# EDMA3TC register map
Vendor: Texas Instruments
Peripheral module from a debugger description file (folder am335x).
Registers are 32-bit, read-only, no defined reset value unless marked. A register's access mark holds for its fields unless they carry their own. Offsets are as the file gives them; lines under a group give offsets from that group; [hi:lo] are bit positions; {n}, {i} and the like mark numbered series; 'fields as' and 'values as' point back to an identical list; <NAME> marks a mode.

## EDMA3TC
0x00 PID — The peripheral identification register (PID) is a constant register that uniquely identifies the EDMA3TC and specific revision of the EDMA3TC.
  [31:0] PID — Peripheral identifier, value 0 to FFFF FFFFh. Reset for PID[31] to PID[16] is 0333h. Reset for PID[15] to PID[0] is 4425h.
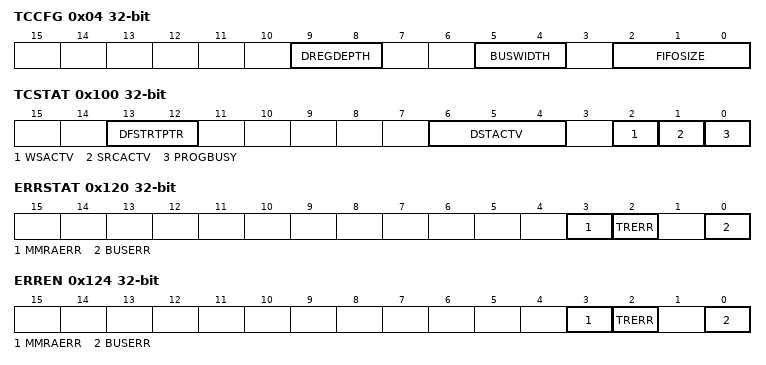
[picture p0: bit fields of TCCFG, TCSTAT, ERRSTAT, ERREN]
0x04 TCCFG
  [9:8] DREGDEPTH — Destination register FIFO depth parameterization.
  [5:4] BUSWIDTH — Bus width parameterization.
  [2:0] FIFOSIZE
0x100 TCSTAT
  [13:12] DFSTRTPTR — Destination FIFO start pointer. Represents the offset to the head entry of the destination register FIFO, in units of entries. Value 0 to 3h.
  [6:4] DSTACTV — Destination active state. Specifies the number of transfer requests (TRs) that are resident in the destination register FIFO at a given instant. This bit field can be primarily used for advanced debugging. Legal values are constrained by the destination register FIFO depth parameterization (DSTREGDEPTH) parameter.
  [2] WSACTV — Write status active
  [1] SRCACTV — Source active state
  [0] PROGBUSY — Program register set busy
0x120 ERRSTAT
  [3] MMRAERR — MMR address error.
  [2] TRERR — Transfer request (TR) error event.
  [0] BUSERR — Bus error event.
0x124 ERREN access per field — When any of the enable bits are set, a bit set in the corresponding ERRSTAT causes an assertion of the EDMA3TC interrupt.
  [3] MMRAERR rw — Interrupt enable for MMR address error (MMRAERR).
  [2] TRERR rw — Interrupt enable for transfer request error (TRERR).
  [0] BUSERR rw — Interrupt enable for bus error (BUSERR).
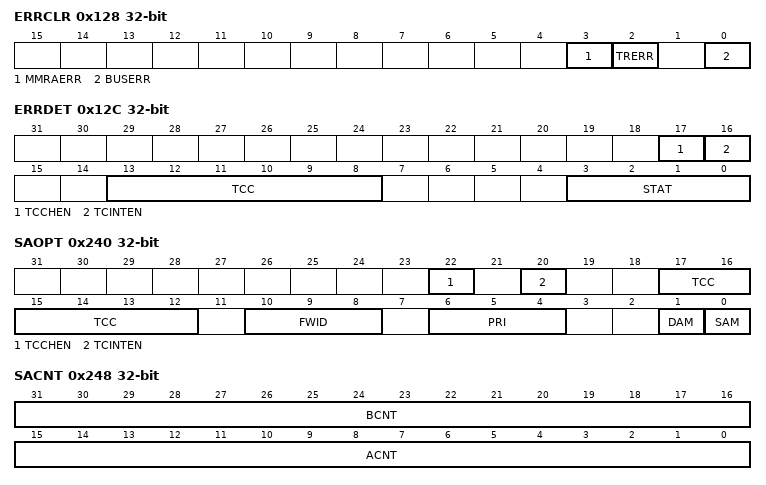
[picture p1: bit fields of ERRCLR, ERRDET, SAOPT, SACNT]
0x128 ERRCLR access per field
  [3] MMRAERR wo — Interrupt enable clear for the MMRAERR bit in the error status register (ERRSTAT).
  [2] TRERR wo — Interrupt enable clear for the TRERR bit in the error status register (ERRSTAT).
  [0] BUSERR wo — Interrupt clear for the BUSERR bit in the error status register (ERRSTAT).
0x12C ERRDET
  [17] TCCHEN — Transfer completion chaining enable. Contains the TCCHEN value in the channel options parameter (OPT) programmed by the channel controller for the read or write transaction that resulted in an error.
  [16] TCINTEN — Transfer completion interrupt enable. Contains the TCINTEN value in the channel options parameter (OPT) programmed by the channel controller for the read or write transaction that resulted in an error.
  [13:8] TCC — Transfer complete code. Contains the TCC value in the channel options parameter (OPT) programmed by the channel controller for the read or write transaction that resulted in an error.
  [3:0] STAT — Transaction status. Stores the nonzero status/error code that was detected on the read status or write status bus. If read status and write status are returned on the same cycle, then the EDMA3TC chooses nonzero version. If both are nonzero, then the write status is treated as higher priority.
0x130 ERRCMD access per field
  [0] EVAL wo — Error evaluate
0x140 RDRATE access per field — The EDMA3 transfer controller issues read commands at a rate controlled by the read rate register (RDRATE). The RDRATE defines the number of idle cycles that the read controller must wait before issuing subsequent commands. This applies both to commands within a transfer request packet (TRP) and for commands that are issued for different transfer requests (TRs). For instance, if RDRATE is set to 4 cycles between reads, there are 3 inactive cycles between reads. RDRATE allows flexibility in transfer controller access requests to an endpoint. For an application, RDRATE can be manipulated to slow down the access rate, so that the endpoint may service requests from other masters during the inactive EDMA3TC cycles. Note: The RDRATE value for a transfer controller is expected to be static, as it is decided based on the application requirement. It is not recommended to change the RDRATE value on the fly.
  [2:0] RDRATE rw — Read rate. Controls the number of cycles between read commands. This is a global setting that applies to all TRs for this EDMA3TC.
0x240 SAOPT access per field — The Source Active Options Register (SAOPT) is an EDMA3TC channel register. The EDMA3TC channel registers are split into three parts: the programming registers, the source active registers, and the destination FIFO register. The program register set is programmed by the channel controller, and is for internal use. The other two sets are read-only and provided to facilitate advanced debug capabilities. The number of destination FIFO register sets depends on the destination FIFO depth. TC0 has a FIFO depth of 2, so there are two sets of destination FIFO registers associated with TC0. TC1, TC2, and TC3 have a destination FIFO depth of 4, so there are four sets of destination FIFO registers for each of these transfer controllers.
  [22] TCCHEN rw — Transfer complete chaining enable
  [20] TCINTEN rw — Transfer complete interrupt enable.
  [17:12] TCC rw — Transfer complete code. This 6 bit code is used to set the relevant bit in CER or IPR of the EDMA3PCC module.
  [10:8] FWID rw — FIFO width. Applies if either SAM or DAM is set to constant addressing mode.
  [6:4] PRI rw — Transfer priority. Reflects the values programmed in the QUEPRI register in the EDMACC.
  [1] DAM rw — Destination address mode within an array
  [0] SAM rw — Source address mode within an array
0x244 SASRC — The Source Active Source Address Register (SASRC) is an EDMA3TC channel register. The EDMA3TC channel registers are split into three parts: the programming registers, the source active registers, and the destination FIFO register. The program register set is programmed by the channel controller, and is for internal use. The other two sets are read-only and provided to facilitate advanced debug capabilities. The number of destination FIFO register sets depends on the destination FIFO depth. TC0 has a FIFO depth of 2, so there are two sets of destination FIFO registers associated with TC0. TC1, TC2, and TC3 have a destination FIFO depth of 4, so there are four sets of destination FIFO registers for each of these transfer controllers.
  [31:0] SADDR — Source address for program register set. EDMA3TC updates value according to source addressing mode (SAM bit in the source active options register, SAOPT). Value 0 to FFFFh.
0x248 SACNT — The Source Active Count Register (SACNT) is an EDMA3TC channel register. The EDMA3TC channel registers are split into three parts: the programming registers, the source active registers, and the destination FIFO register. The program register set is programmed by the channel controller, and is for internal use. The other two sets are read-only and provided to facilitate advanced debug capabilities. The number of destination FIFO register sets depends on the destination FIFO depth. TC0 has a FIFO depth of 2, so there are two sets of destination FIFO registers associated with TC0. TC1, TC2, and TC3 have a destination FIFO depth of 4, so there are four sets of destination FIFO registers for each of these transfer controllers.
  [31:16] BCNT — B dimension count. Number of arrays to be transferred, where each array is ACNT in length. It is decremented after each read command appropriately. Represents the amount of data remaining to be read. It should be 0 when transfer request (TR) is complete. Value 0 to FFFFh.
  [15:0] ACNT — A dimension count. Number of bytes to be transferred in first dimension. It is decremented after each read command appropriately. Represents the amount of data remaining to be read. It should be 0 when transfer request (TR) is complete. Value 0 to FFFFh.
0x24C SADST — The Source Active Destination Address Register (SADST) is an EDMA3TC channel register. The EDMA3TC channel registers are split into three parts: the programming registers, the source active registers, and the destination FIFO register. The program register set is programmed by the channel controller, and is for internal use. The other two sets are read-only and provided to facilitate advanced debug capabilities. The number of destination FIFO register sets depends on the destination FIFO depth. TC0 has a FIFO depth of 2, so there are two sets of destination FIFO registers associated with TC0. TC1, TC2, and TC3 have a destination FIFO depth of 4, so there are four sets of destination FIFO registers for each of these transfer controllers.
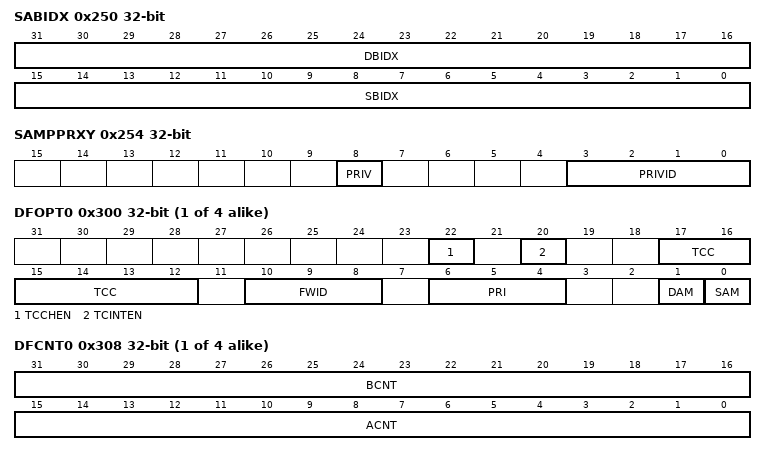
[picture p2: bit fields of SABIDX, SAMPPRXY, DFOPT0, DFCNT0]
0x250 SABIDX — The Source Active Source B-Dimension Index Register (SABIDX) is an EDMA3TC channel register. The EDMA3TC channel registers are split into three parts: the programming registers, the source active registers, and the destination FIFO register. The program register set is programmed by the channel controller, and is for internal use. The other two sets are read-only and provided to facilitate advanced debug capabilities. The number of destination FIFO register sets depends on the destination FIFO depth. TC0 has a FIFO depth of 2, so there are two sets of destination FIFO registers associated with TC0. TC1, TC2, and TC3 have a destination FIFO depth of 4, so there are four sets of destination FIFO registers for each of these transfer controllers.
  [31:16] DBIDX — B-Index offset between destination arrays. Represents the offset in bytes between the starting address of each destination. Always reads as 0.
  [15:0] SBIDX — B-Index offset between source arrays. Represents the offset in bytes between the starting address of each source array. Value 0 to FFFFh.
0x254 SAMPPRXY — The Source Active Memory Protection Proxy Register (SAMPPRXY) is an EDMA3TC channel register. The EDMA3TC channel registers are split into three parts: the programming registers, the source active registers, and the destination FIFO register. The program register set is programmed by the channel controller, and is for internal use. The other two sets are read-only and provided to facilitate advanced debug capabilities. The number of destination FIFO register sets depends on the destination FIFO depth. TC0 has a FIFO depth of 2, so there are two sets of destination FIFO registers associated with TC0. TC1, TC2, and TC3 have a destination FIFO depth of 4, so there are four sets of destination FIFO registers for each of these transfer controllers.
  [8] PRIV — Privilege level. The privilege level used by the host to set up the parameter entry in the channel controller. This field is set up when the associated TR is submitted to the EDMA3TC. The privilege ID is used while issuing read and write command to the target endpoints so that the target endpoints can perform memory protection checks based on the PRIV of the host that set up the DMA transaction.
  [3:0] PRIVID — Privilege ID. This contains the privilege ID of the host that set up the parameter entry in the channel controller. This field is set up when the associated TR is submitted to the EDMA3TC. This PRIVID value is used while issuing read and write commands to the target endpoints so that the target endpoints can perform memory protection checks based on the PRIVID of the host that set up the DMA transaction. Value 0 to Fh.
0x258 SACNTRLD — The Source Active Count Reload Register (SACNTRLD) is an EDMA3TC channel register. The EDMA3TC channel registers are split into three parts: the programming registers, the source active registers, and the destination FIFO register. The program register set is programmed by the channel controller, and is for internal use. The other two sets are read-only and provided to facilitate advanced debug capabilities. The number of destination FIFO register sets depends on the destination FIFO depth. TC0 has a FIFO depth of 2, so there are two sets of destination FIFO registers associated with TC0. TC1, TC2, and TC3 have a destination FIFO depth of 4, so there are four sets of destination FIFO registers for each of these transfer controllers.
  [15:0] ACNTRLD — A-count reload value. Represents the originally programmed value of ACNT. The reload value is used to reinitialize ACNT after each array is serviced. Value 0 to FFFFh.
0x25C SASRCBREF — The Source Active Source Address B-Reference Register (SASRCBREF) is an EDMA3TC channel register. The EDMA3TC channel registers are split into three parts: the programming registers, the source active registers, and the destination FIFO register. The program register set is programmed by the channel controller, and is for internal use. The other two sets are read-only and provided to facilitate advanced debug capabilities. The number of destination FIFO register sets depends on the destination FIFO depth. TC0 has a FIFO depth of 2, so there are two sets of destination FIFO registers associated with TC0. TC1, TC2, and TC3 have a destination FIFO depth of 4, so there are four sets of destination FIFO registers for each of these transfer controllers.
  [31:0] SADDRBREF — Source address B-reference. Represents the starting address for the array currently being read. Value 0 to FFFF FFFFh.
0x260 SADSTBREF — The Source Active Destination Address B-Reference Register (SADSTBREF) is an EDMA3TC channel register. The EDMA3TC channel registers are split into three parts: the programming registers, the source active registers, and the destination FIFO register. The program register set is programmed by the channel controller, and is for internal use. The other two sets are read-only and provided to facilitate advanced debug capabilities. The number of destination FIFO register sets depends on the destination FIFO depth. TC0 has a FIFO depth of 2, so there are two sets of destination FIFO registers associated with TC0. TC1, TC2, and TC3 have a destination FIFO depth of 4, so there are four sets of destination FIFO registers for each of these transfer controllers.
0x280 DFCNTRLD — The Destination FIFO Count Reload Register (DFCNTRLD) is an EDMA3TC channel register. The EDMA3TC channel registers are split into three parts: the programming registers, the source active registers, and the destination FIFO register. The program register set is programmed by the channel controller, and is for internal use. The other two sets are read-only and provided to facilitate advanced debug capabilities. The number of destination FIFO register sets depends on the destination FIFO depth. TC0 has a FIFO depth of 2, so there are two sets of destination FIFO registers associated with TC0. TC1, TC2, and TC3 have a destination FIFO depth of 4, so there are four sets of destination FIFO registers for each of these transfer controllers.
  fields as SACNTRLD
0x284 DFSRCBREF — The Destination FIFO Source Address B-Reference Register (DFSRCBREF) is an EDMA3TC channel register. The EDMA3TC channel registers are split into three parts: the programming registers, the source active registers, and the destination FIFO register. The program register set is programmed by the channel controller, and is for internal use. The other two sets are read-only and provided to facilitate advanced debug capabilities. The number of destination FIFO register sets depends on the destination FIFO depth. TC0 has a FIFO depth of 2, so there are two sets of destination FIFO registers associated with TC0. TC1, TC2, and TC3 have a destination FIFO depth of 4, so there are four sets of destination FIFO registers for each of these transfer controllers.
0x288 DFDSTBREF — The Destination FIFO Destination Address B-Reference Register (DFDSTBREF) is an EDMA3TC channel register. The EDMA3TC channel registers are split into three parts: the programming registers, the source active registers, and the destination FIFO register. The program register set is programmed by the channel controller, and is for internal use. The other two sets are read-only and provided to facilitate advanced debug capabilities. The number of destination FIFO register sets depends on the destination FIFO depth. TC0 has a FIFO depth of 2, so there are two sets of destination FIFO registers associated with TC0. TC1, TC2, and TC3 have a destination FIFO depth of 4, so there are four sets of destination FIFO registers for each of these transfer controllers.
  [31:0] DADDRBREF — Destination address reference for the destination FIFO register set. Represents the starting address for the array currently being written. Value 0 to FFFF FFFFh.
{0x300+0x40*i} DFOPT{i} access per field (i=0..3) — The Destination FIFO Options Register (DFOPT) is an EDMA3TC channel register. The EDMA3TC channel registers are split into three parts: the programming registers, the source active registers, and the destination FIFO register. The program register set is programmed by the channel controller, and is for internal use. The other two sets are read-only and provided to facilitate advanced debug capabilities. The number of destination FIFO register sets depends on the destination FIFO depth. TC0 has a FIFO depth of 2, so there are two sets of destination FIFO registers associated with TC0. TC1, TC2, and TC3 have a destination FIFO depth of 4, so there are four sets of destination FIFO registers for each of these transfer controllers.
  [22] TCCHEN rw — Transfer complete chaining enable
  [20] TCINTEN rw — Transfer complete interrupt enable.
  [17:12] TCC rw — Transfer complete code. This 6 bit code is used to set the relevant bit in CER or IPR of the EDMA3PCC module.
  [10:8] FWID rw — FIFO width. Applies if either SAM or DAM is set to constant addressing mode.
  [6:4] PRI rw — Transfer priority
  [1] DAM rw — Destination address mode within an array
  [0] SAM rw — Source address mode within an array
{0x304+0x40*i} DFSRC{i} (i=0..3) — The Destination FIFO Source Address Register (DFSRC) is an EDMA3TC channel register. The EDMA3TC channel registers are split into three parts: the programming registers, the source active registers, and the destination FIFO register. The program register set is programmed by the channel controller, and is for internal use. The other two sets are read-only and provided to facilitate advanced debug capabilities. The number of destination FIFO register sets depends on the destination FIFO depth. TC0 has a FIFO depth of 2, so there are two sets of destination FIFO registers associated with TC0. TC1, TC2, and TC3 have a destination FIFO depth of 4, so there are four sets of destination FIFO registers for each of these transfer controllers.
{0x308+0x40*i} DFCNT{i} (i=0..3) — The Destination FIFO Count Register (DFCNT) is an EDMA3TC channel register. The EDMA3TC channel registers are split into three parts: the programming registers, the source active registers, and the destination FIFO register. The program register set is programmed by the channel controller, and is for internal use. The other two sets are read-only and provided to facilitate advanced debug capabilities. The number of destination FIFO register sets depends on the destination FIFO depth. TC0 has a FIFO depth of 2, so there are two sets of destination FIFO registers associated with TC0. TC1, TC2, and TC3 have a destination FIFO depth of 4, so there are four sets of destination FIFO registers for each of these transfer controllers.
  [31:16] BCNT — B-dimension count. Number of arrays to be transferred, where each array is ACNT in length. Count/count remaining for destination register set. Represents the amount of data remaining to be written. Value 0 to FFFFh.
  [15:0] ACNT — A-dimension count. Number of bytes to be transferred in first dimension count/count remaining for destination register set. Represents the amount of data remaining to be written. Value 0 to FFFFh.
{0x30C+0x40*i} DFDST{i} (i=0..3) — The Destination FIFO Destination Address Register (DFDST) is an EDMA3TC channel register. The EDMA3TC channel registers are split into three parts: the programming registers, the source active registers, and the destination FIFO register. The program register set is programmed by the channel controller, and is for internal use. The other two sets are read-only and provided to facilitate advanced debug capabilities. The number of destination FIFO register sets depends on the destination FIFO depth. TC0 has a FIFO depth of 2, so there are two sets of destination FIFO registers associated with TC0. TC1, TC2, and TC3 have a destination FIFO depth of 4, so there are four sets of destination FIFO registers for each of these transfer controllers.
  [31:0] DADDR — Destination address for the destination FIFO register set. When a transfer request (TR) is complete, the final value should be the address of the last write command issued.
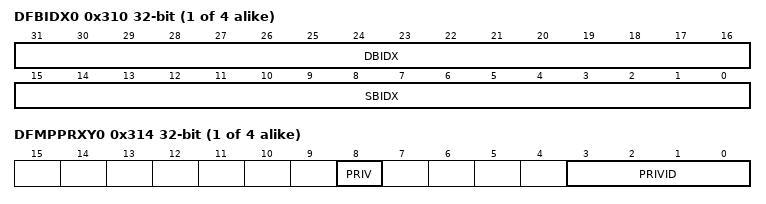
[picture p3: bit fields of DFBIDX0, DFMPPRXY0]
{0x310+0x40*i} DFBIDX{i} (i=0..3) — The Destination FIFO B-Index Register (DFBIDX) is an EDMA3TC channel register. The EDMA3TC channel registers are split into three parts: the programming registers, the source active registers, and the destination FIFO register. The program register set is programmed by the channel controller, and is for internal use. The other two sets are read-only and provided to facilitate advanced debug capabilities. The number of destination FIFO register sets depends on the destination FIFO depth. TC0 has a FIFO depth of 2, so there are two sets of destination FIFO registers associated with TC0. TC1, TC2, and TC3 have a destination FIFO depth of 4, so there are four sets of destination FIFO registers for each of these transfer controllers.
  [31:16] DBIDX — B-Index offset between destination arrays. Represents the offset in bytes between the starting address of each destination. Value 0 to FFFFh.
  [15:0] SBIDX — Always read as 0.
{0x314+0x40*i} DFMPPRXY{i} (i=0..3) — The Destination FIFO Memory Protection Proxy Register (DFMPPRXY) is an EDMA3TC channel register. The EDMA3TC channel registers are split into three parts: the programming registers, the source active registers, and the destination FIFO register. The program register set is programmed by the channel controller, and is for internal use. The other two sets are read-only and provided to facilitate advanced debug capabilities. The number of destination FIFO register sets depends on the destination FIFO depth. TC0 has a FIFO depth of 2, so there are two sets of destination FIFO registers associated with TC0. TC1, TC2, and TC3 have a destination FIFO depth of 4, so there are four sets of destination FIFO registers for each of these transfer controllers.
  [8] PRIV — Privilege level. This contains the Privilege level used by the EDMA3 programmer to set up the parameter entry in the channel controller. This field is set up when the associated TR is submitted to the EDMA3TC. The privilege ID is used while issuing read and write command to the target endpoints so that the target endpoints can perform memory protection checks based on the PRIV of the host that set up the DMA transaction.
  [3:0] PRIVID — Privilege ID. This contains the Privilege ID of the EDMA3 programmer that set up the parameter entry in the channel controller. This field is set up when the associated TR is submitted to the EDMA3TC. This PRIVID value is used while issuing read and write commands to the target endpoints so that the target endpoints can perform memory protection checks based on the PRIVID of the host that set up the DMA transaction. Value 0 to Fh.
